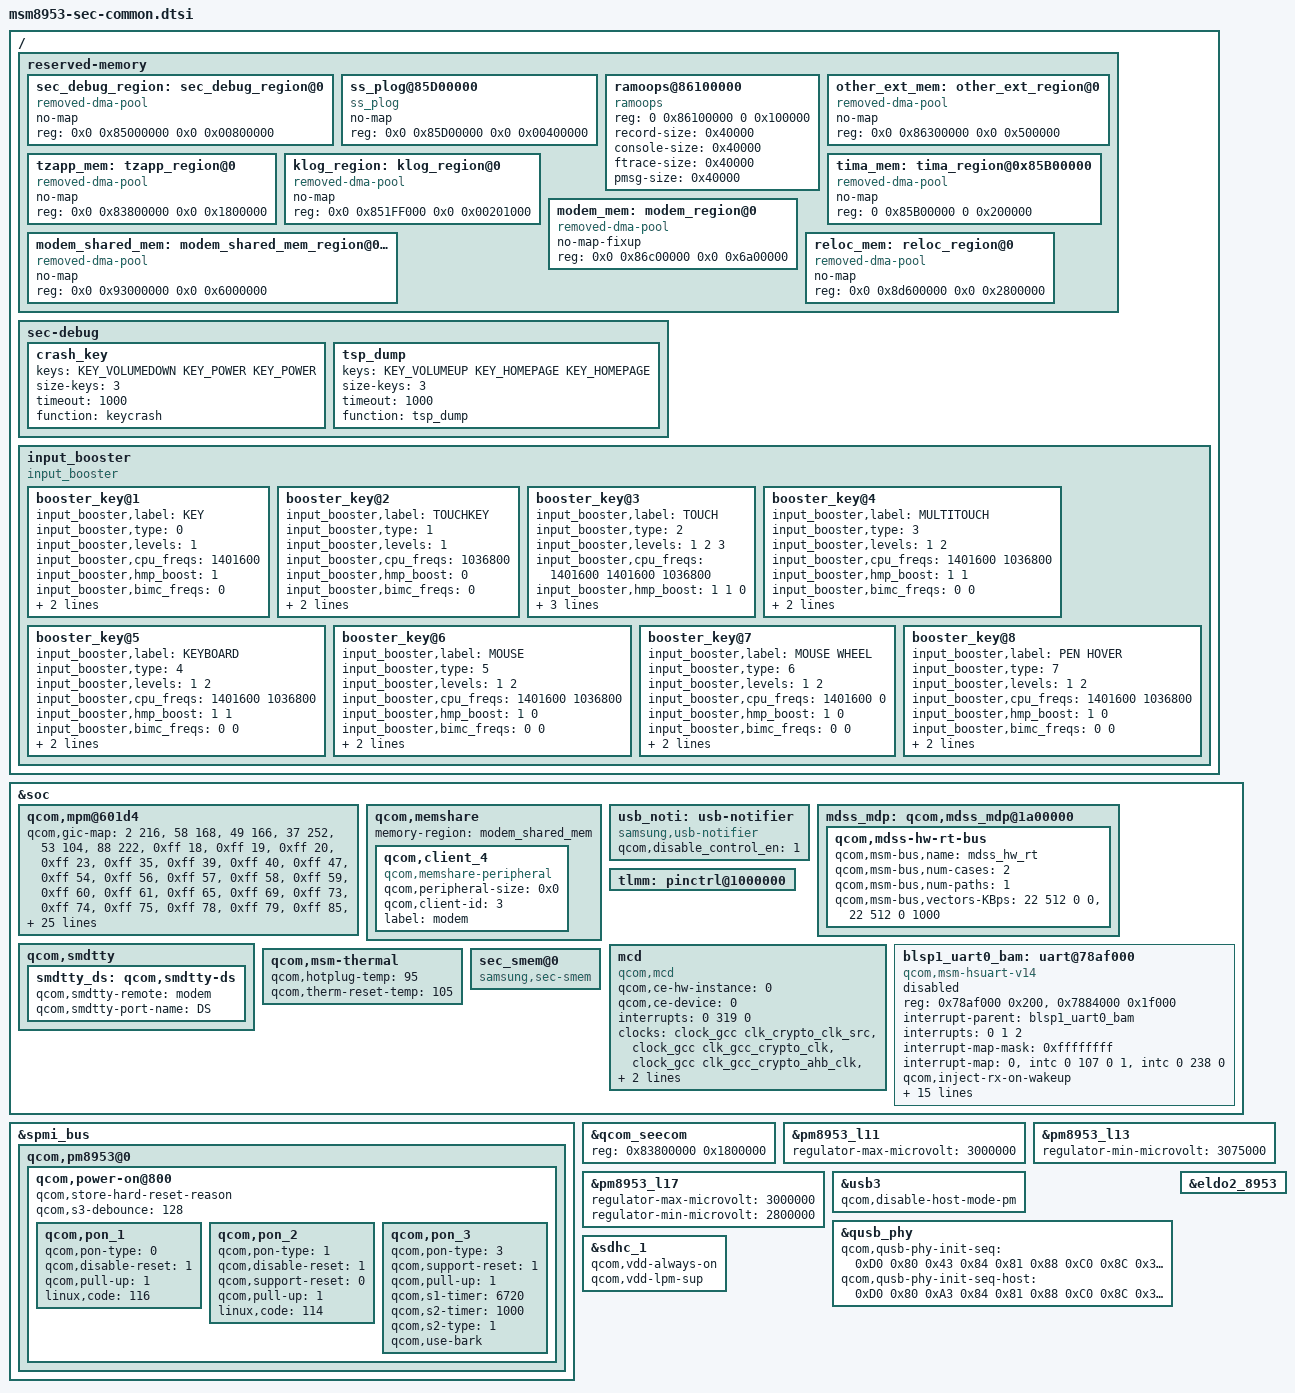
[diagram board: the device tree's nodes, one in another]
/*
 * Copyright (c) 2015-2016, The Linux Foundation. All rights reserved.
 *
 * This program is free software; you can redistribute it and/or modify
 * it under the terms of the GNU General Public License version 2 and
 * only version 2 as published by the Free Software Foundation.
 *
 * This program is distributed in the hope that it will be useful,
 * but WITHOUT ANY WARRANTY; without even the implied warranty of
 * MERCHANTABILITY or FITNESS FOR A PARTICULAR PURPOSE.  See the
 * GNU General Public License for more details.
 */

#include <dt-bindings/input/input.h>

/ {
	reserved-memory {
		/* CONFIG_SEC_DEBUG reserves 8MB */
		sec_debug_region: sec_debug_region@0 {
			compatible = "removed-dma-pool";
			no-map;
			reg = <0x0 0x85000000 0x0 0x00800000>;
		};
		ss_plog@85D00000 {
			compatible = "ss_plog";
			no-map;
			reg = <0x0 0x85D00000 0x0 0x00400000>;
		};
		ramoops@86100000 {
			compatible = "ramoops";
			reg = <0 0x86100000 0 0x100000>;
			record-size = <0x40000>;
			console-size = <0x40000>;
			ftrace-size = <0x40000>;
			pmsg-size = <0x40000>;
		};
		other_ext_mem: other_ext_region@0 {
			compatible = "removed-dma-pool";
			no-map;
			reg = <0x0 0x86300000 0x0 0x500000>;
		};
		tzapp_mem: tzapp_region@0 {
			compatible = "removed-dma-pool";
			no-map;
			reg = <0x0 0x83800000 0x0 0x1800000>;
		};

		/* klog_region reserves 2.01MB
		   This region is reserved if only debuglevel low */
		klog_region: klog_region@0 {
			compatible = "removed-dma-pool";
			no-map;
			reg = <0x0 0x851FF000 0x0 0x00201000>;
		};

		/*to reserve 2MB for TIMA */
		tima_mem: tima_region@0x85B00000 {
		    compatible = "removed-dma-pool";
		    no-map;
		    reg = <0 0x85B00000 0 0x200000>;
		};

		modem_shared_mem: modem_shared_mem_region@0x93000000 {
			compatible = "removed-dma-pool";
			no-map;
			reg = <0x0 0x93000000 0x0 0x6000000>;
		};

		/delete-node/ modem_region@0;
		modem_mem: modem_region@0 {
			compatible = "removed-dma-pool";
			no-map-fixup;
			reg = <0x0 0x86c00000 0x0 0x6a00000>;
		};

		/delete-node/ reloc_region@0;
		reloc_mem: reloc_region@0 {
			compatible = "removed-dma-pool";
			no-map;
			reg = <0x0 0x8d600000 0x0 0x2800000>;
		};
	};

	sec-debug {
		crash_key {
			keys = <KEY_VOLUMEDOWN KEY_POWER KEY_POWER>;
			size-keys = <3>;
			timeout = <1000>;	/* default = 1000msec */
			function = "keycrash";
		};

		 tsp_dump {
			keys = <KEY_VOLUMEUP KEY_HOMEPAGE KEY_HOMEPAGE>;
			size-keys = <3>;
			timeout = <1000>;
			function = "tsp_dump";
		};
	};

	input_booster {
		status = "okay";
		compatible = "input_booster";
		#address-cells = <1>;
		#size-cells = <0>;

		booster_key@1 {
			input_booster,label = "KEY";
			input_booster,type = <0>;	/* BOOSTER_DEVICE_KEY */

			input_booster,levels = <1>;

			/* Frequency table */
			/* for level	:	1_Head */
			input_booster,cpu_freqs = <1401600>;
			input_booster,hmp_boost = <1>;
			input_booster,bimc_freqs = <0>;

			/* Time table */
			input_booster,head_times = <200>;
			input_booster,tail_times = <200>;

		};
		booster_key@2 {
			input_booster,label = "TOUCHKEY";
			input_booster,type = <1>;	/* BOOSTER_DEVICE_TOUCHKEY */

			input_booster,levels = <1>;

			/* Frequency table */
			/* for level	:	1_Head */
			input_booster,cpu_freqs = <1036800>;
			input_booster,hmp_boost = <0>;
			input_booster,bimc_freqs = <0>;

			/* Time table */
			input_booster,head_times = <0>;
			input_booster,tail_times = <300>;
		};
		booster_key@3 {
			input_booster,label = "TOUCH";
			input_booster,type = <2>;	/* BOOSTER_DEVICE_TOUCH */

			input_booster,levels = <1 2 3>;

			/* Frequency table */
			/* for level	:	1_Head, 2_Head, 2_Tail */
			input_booster,cpu_freqs = <1401600 1401600 1036800>;
			input_booster,hmp_boost = <1 1 0>;
			input_booster,bimc_freqs = <0 0 0>;

			/* Time table */
			input_booster,head_times = <200 200 0>;
			input_booster,tail_times = <0 0 300>;
		};
		booster_key@4 { // Input Booster +
			input_booster,label = "MULTITOUCH";
			input_booster,type = <3>;	/* BOOSTER_DEVICE_MULTITOUCH */

			input_booster,levels = <1 2>;

			/* Frequency table */
			/* for level	:	1_Head 2_Tail*/
			input_booster,cpu_freqs = <1401600 1036800>;
			input_booster,hmp_boost = <1 1>;
			input_booster,bimc_freqs = <0 0>;

			/* Time table */
			input_booster,head_times = <1000 0>;
			input_booster,tail_times = <0 500>;
		};
		booster_key@5 {
			input_booster,label = "KEYBOARD";
			input_booster,type = <4>;	/* BOOSTER_DEVICE_KEYBOARD */

			input_booster,levels = <1 2>;

			/* Frequency table */
			/* for level	:	1_Head 2_Tail*/
			input_booster,cpu_freqs = <1401600 1036800>;
			input_booster,hmp_boost = <1 1>;
			input_booster,bimc_freqs = <0 0>;

			/* Time table */
			input_booster,head_times = <200 200>;
			input_booster,tail_times = <0 0>;
		};
		booster_key@6 {
			input_booster,label = "MOUSE";
			input_booster,type = <5>;	/* BOOSTER_DEVICE_MOUSE */

			input_booster,levels = <1 2>;

			/* Frequency table */
			/* for level	:	1_Head 2_Tail*/
			input_booster,cpu_freqs = <1401600 1036800>;
			input_booster,hmp_boost = <1 0>;
			input_booster,bimc_freqs = <0 0>;

			/* Time table */
			input_booster,head_times = <200 0>;
			input_booster,tail_times = <0 300>;
		};
		booster_key@7 {
			input_booster,label = "MOUSE WHEEL";
			input_booster,type = <6>;	/* BOOSTER_DEVICE_MOUSE */

			input_booster,levels = <1 2>;

			/* Frequency table */
			/* for level	:	1_Head 2_Tail*/
			input_booster,cpu_freqs = <1401600 0>;
			input_booster,hmp_boost = <1 0>;
			input_booster,bimc_freqs = <0 0>;

			/* Time table */
			input_booster,head_times = <200 0>;
			input_booster,tail_times = <0 0>;
		};
		booster_key@8 {
			input_booster,label = "PEN HOVER";
			input_booster,type = <7>;	/* BOOSTER_DEVICE_MOUSE */

			input_booster,levels = <1 2>;

			/* Frequency table */
			/* for level	:	1_Head 2_Tail*/
			input_booster,cpu_freqs = <1401600 1036800>;
			input_booster,hmp_boost = <1 0>;
			input_booster,bimc_freqs = <0 0>;

			/* Time table */
			input_booster,head_times = <200 0>;
			input_booster,tail_times = <0 300>;
		}; // Input Booster -
		/* If you need to add new key type, add it this position */
	};
};

&soc {
	qcom,mpm@601d4 {
			/delete-property/ qcom,gic-map;
			qcom,gic-map = <2 216>, /* tsens_upper_lower_int */
			<58 168>,   /* qusb2phy_dmse_hv -> hs_phy_irq*/
			<49 166>,   /* qusb2phy_dpse_hv -> usb30_pwr_evnt_irq */
			<37 252>,   /* qmp_usb3_lfps_rxterm_irq -> ss_phy_irq */
			<53 104>, /* mdss_irq */
			<88 222>, /* ee0_krait_hlos_spmi_periph_irq */
			<0xff 18>,  /* APC_qgicQTmrSecPhysIrptReq */
			<0xff 19>,  /* APC_qgicQTmrNonSecPhysIrptReq */
			<0xff 20>,  /* qgicQTmrVirtIrptReq */
			<0xff 23>,  /* apss_hm */
			<0xff 35>,  /* WDT_barkInt */
			<0xff 39>,  /* arch_mem_timer */
			<0xff 40>,  /* qtmr_phy_irq[0] */
			<0xff 47>,  /* rbif_irq[0] */
			<0xff 54>,  /* gladiator-error */
			<0xff 56>,  /* q6_wdog_expired_irq */
			<0xff 57>,  /* mss_to_apps_irq(0) */
			<0xff 58>,  /* mss_to_apps_irq(1) */
			<0xff 59>,  /* mss_to_apps_irq(2) */
			<0xff 60>,  /* mss_to_apps_irq(3) */
			<0xff 61>,  /* mss_a2_bam_irq */
			<0xff 65>,  /* o_gc_sys_irq[0] */
			<0xff 69>,  /* vbif_irpt */
			<0xff 73>,  /* app_tcu_gbl_flt_irpt_ns */
			<0xff 74>,  /* smmu_bus_intr[2] */
			<0xff 75>,  /* smmu_bus_intr[3] */
			<0xff 78>,  /* smmu_bus_intr[5] */
			<0xff 79>,  /* smmu_bus_intr[6] */
			<0xff 85>,  /* smmu_bus_intr[31] */
			<0xff 86>,  /* smmu_bus_intr[32] */
			<0xff 90>,  /* smmu_bus_intr[33] */
			<0xff 92>,  /* smmu_bus_intr[34] */
			<0xff 93>,  /* smmu_bus_intr[35] */
			<0xff 97>,  /* smmu_bus_intr[10] */
			<0xff 102>, /* smmu_bus_intr[14] */
			<0xff 108>, /* smmu_bus_intr[36] */
			<0xff 109>, /* smmu_bus_intr[37] */
			<0xff 112>, /* smmu_bus_intr[38] */
			<0xff 114>, /* qdsd_intr_out */
			<0xff 126>, /* app_tcu_cxt_irpt_vec[11] */
			<0xff 128>, /* blsp1_peripheral_irq[3] */
			<0xff 131>, /* qup_irq */
			<0xff 136>, /* app_tcu_cxt_irpt_vec[15] */
			<0xff 137>, /* app_tcu_cxt_irpt_vec[16] */
			<0xff 138>, /* app_tcu_cxt_irpt_vec[17] */
			<0xff 139>, /* uart_dm_intr */
			<0xff 140>, /* uart_dm_intr */
			<0xff 141>, /* app_tcu_cxt_irpt_vec[18] */
			<0xff 142>, /* smmu_bus_intr[47] */
			<0xff 143>, /* smmu_bus_intr[48] */
			<0xff 144>, /* smmu_bus_intr[49] */
			<0xff 145>, /* smmu_bus_intr[50] */
			<0xff 146>, /* smmu_bus_intr[51] */
			<0xff 147>, /* smmu_bus_intr[52] */
			<0xff 148>, /* smmu_bus_intr[53] */
			<0xff 149>, /* smmu_bus_intr[54] */
			<0xff 150>, /* smmu_bus_intr[55] */
			<0xff 151>, /* smmu_bus_intr[56] */
			<0xff 152>, /* smmu_bus_intr[57] */
			<0xff 153>, /* smmu_bus_intr[58] */
			<0xff 155>, /* sdc1_irq(0) */
			<0xff 157>, /* sdc2_irq(0) */
			<0xff 167>, /* usb30_bam_irq[0] */
			<0xff 170>, /* sdc1_pwr_cmd_irq */
			<0xff 172>, /* usb30_ctrl_irq[0] */
			<0xff 173>, /* o_wcss_apss_smd_hi */
			<0xff 174>, /* o_wcss_apss_smd_med */
			<0xff 175>, /* o_wcss_apss_smd_low */
			<0xff 176>, /* o_wcss_apss_smsm_irq */
			<0xff 177>, /* o_wcss_apss_wlan_data_xfer_done */
			<0xff 178>, /* o_wcss_apss_wlan_rx_data_avail */
			<0xff 179>, /* o_wcss_apss_asic_intr */
			<0xff 181>, /* o_wcss_apss_wdog_bite_and_reset_rdy */
			<0xff 188>, /* lpass_irq_out_apcs(0) */
			<0xff 189>, /* lpass_irq_out_apcs(1) */
			<0xff 190>, /* lpass_irq_out_apcs(2) */
			<0xff 191>, /* lpass_irq_out_apcs(3) */
			<0xff 192>, /* lpass_irq_out_apcs(4) */
			<0xff 193>, /* lpass_irq_out_apcs(5) */
			<0xff 194>, /* lpass_irq_out_apcs(6) */
			<0xff 195>, /* lpass_irq_out_apcs(7) */
			<0xff 196>, /* lpass_irq_out_apcs(8) */
			<0xff 197>, /* lpass_irq_out_apcs(9) */
			<0xff 198>, /* coresight-tmc-etr interrupt */
			<0xff 200>, /* rpm_ipc(4) */
			<0xff 201>, /* rpm_ipc(5) */
			<0xff 202>, /* rpm_ipc(6) */
			<0xff 203>, /* rpm_ipc(7) */
			<0xff 204>, /* rpm_ipc(24) */
			<0xff 205>, /* rpm_ipc(25) */
			<0xff 206>, /* rpm_ipc(26) */
			<0xff 207>, /* rpm_ipc(27) */
			<0xff 212>, /* lpass_slimbus_bam_ee1_irq */
			<0xff 215>, /* o_bimc_intr[0] */
			<0xff 224>, /* spdm_realtime_irq[1] */
			<0xff 231>, /* arm-smmu global fault */
			<0xff 239>, /* crypto_bam_irq[1]*/
			<0xff 240>, /* summary_irq_kpss */
			<0xff 253>, /* sdc2_pwr_cmd_irq */
			<0xff 257>, /* osmmu_Cirpt[0] */
			<0xff 260>, /* ipa_irq[0] */
			<0xff 262>, /* ipa_bam_irq[0] */
			<0xff 263>, /* ipa_bam_irq[2] */
			<0xff 264>, /* arm-smmu context fault */
			<0xff 269>, /* rpm_wdog_expired_irq */
			<0xff 270>, /* blsp1_bam_irq[0] */
			<0xff 271>,
			<0xff 273>, /* smmu_bus_intr[18] */
			<0xff 274>, /* smmu_bus_intr[19] */
			<0xff 275>, /* rpm_ipc(30) */
			<0xff 276>, /* rpm_ipc(31) */
			<0xff 285>, /* app_tcu_cxt_irpt_vec[0] */
			<0xff 286>, /* app_tcu_cxt_irpt_vec[1] */
			<0xff 287>, /* app_tcu_cxt_irpt_vec[2] */
			<0xff 305>, /* L2_EXTERRIRQ_C0 */
			<0xff 306>, /* L2_EXTERRIRQ_C1 */
			<0xff 307>, /* L2_INTERRIRQ_C0 */
			<0xff 308>, /* L2_INTERRIRQ_C1 */
			<0xff 314>, /* CCISAW_svicInt */
			<0xff 321>, /* q6ss_irq_out(4) */
			<0xff 322>, /* q6ss_irq_out(5) */
			<0xff 323>, /* q6ss_irq_out(6) */
			<0xff 325>, /* q6ss_wdog_exp_irq */
			<0xff 331>,
			<0xff 344>, /* sdcc_ice_nonsec_level_irq */
			<0xff 346>, /* tsens_critical_int */
			<0xff 351>; /* trustonic */
	};

	qcom,memshare {
		memory-region = <&modem_shared_mem>;

		qcom,client_4 {
			compatible = "qcom,memshare-peripheral";
			qcom,peripheral-size = <0x0>;
			qcom,client-id = <3>;	/* vendor */
			label = "modem";
		};
	};

	usb_noti:usb-notifier {
		compatible = "samsung,usb-notifier";
		qcom,disable_control_en = <1>;
	};

	mdss_mdp: qcom,mdss_mdp@1a00000 {
		qcom,mdss-hw-rt-bus {
			/* Bus Scale Settings */
			qcom,msm-bus,name = "mdss_hw_rt";
			qcom,msm-bus,num-cases = <2>;
			qcom,msm-bus,num-paths = <1>;
			qcom,msm-bus,vectors-KBps =
				<22 512 0 0>,
				<22 512 0 1000>;
		};
	};

	tlmm: pinctrl@1000000 {
		/delete-node/ pmx_rd_nfc_int;
	};


	qcom,smdtty {
		smdtty_ds: qcom,smdtty-ds {
			qcom,smdtty-remote = "modem";
			qcom,smdtty-port-name = "DS";
		};
	};

	mcd: mcd {
		compatible = "qcom,mcd";
		qcom,ce-hw-instance = <0>;
		qcom,ce-device = <0>;
		interrupts = <0 319 0>;
		interrupt-names = "mcd_irq";
		clocks = <&clock_gcc clk_crypto_clk_src>,
			 <&clock_gcc clk_gcc_crypto_clk>,
			 <&clock_gcc clk_gcc_crypto_ahb_clk>,
			 <&clock_gcc clk_gcc_crypto_axi_clk>;
		clock-names = "core_clk_src", "core_clk",
				"iface_clk", "bus_clk";
		qcom,ce-opp-freq = <100000000>;
	};

	blsp1_uart0_bam: uart@78af000 {
		compatible = "qcom,msm-hsuart-v14";
		reg = <0x78af000 0x200>,
			<0x7884000 0x1f000>;
		reg-names = "core_mem", "bam_mem";

		interrupt-names = "core_irq", "bam_irq";
		#address-cells = <0>;
		interrupt-parent = <&blsp1_uart0_bam>;
		interrupts = <0 1 2>;
		#interrupt-cells = <1>;
		interrupt-map-mask = <0xffffffff>;
		interrupt-map = <0 &intc 0 107 0
				1 &intc 0 238 0>;

		qcom,inject-rx-on-wakeup;
		qcom,rx-char-to-inject = <0xFD>;
		qcom,master-id = <86>;
		clock-names = "core_clk", "iface_clk";
		clocks = <&clock_gcc clk_gcc_blsp1_uart1_apps_clk>,
			<&clock_gcc clk_gcc_blsp1_ahb_clk>;
		pinctrl-names = "sleep", "default";
		pinctrl-0 = <&hsuart_sleep>;
		pinctrl-1 = <&hsuart_active>;
		qcom,bam-tx-ep-pipe-index = <0>;
		qcom,bam-rx-ep-pipe-index = <1>;
		qcom,msm-bus,name = "blsp1_uart0_bam";
		qcom,msm-bus,num-cases = <2>;
		qcom,msm-bus,num-paths = <1>;
		qcom,msm-bus,vectors-KBps =
				<86 512 0 0>,
				<86 512 500 800>;
		status = "disabled";
		qcom,unuse-pm;
	};
	
	qcom,msm-thermal {
		qcom,hotplug-temp = <95>;
		qcom,therm-reset-temp = <105>;
	};

	sec_smem@0 {
		compatible = "samsung,sec-smem";
		status = "okay";
	};
};

&spmi_bus {
	qcom,pm8953@0 {
		qcom,power-on@800 {
			qcom,store-hard-reset-reason;

			qcom,s3-debounce = <128>;
			qcom,pon_1 {
				qcom,pon-type = <0>;
				qcom,disable-reset = <1>;
				qcom,pull-up = <1>;
				linux,code = <116>;
			};

			qcom,pon_2 {
				qcom,pon-type = <1>;
				qcom,disable-reset = <1>;
				qcom,support-reset = <0>;
				qcom,pull-up = <1>;
				linux,code = <114>;
			};

			qcom,pon_3 {
				qcom,pon-type = <3>;
				qcom,support-reset = <1>;
				qcom,pull-up = <1>;
				qcom,s1-timer = <6720>;
				qcom,s2-timer = <1000>;
				qcom,s2-type = <1>;
				qcom,use-bark;
			};
		};


	};
};

&qcom_seecom {
	reg = <0x83800000 0x1800000>;
};

&pm8953_l11 {
	regulator-max-microvolt = <3000000>;
};

&pm8953_l13 {
	regulator-min-microvolt = <3075000>;
};

&pm8953_l17 {
	regulator-max-microvolt = <3000000>;
	regulator-min-microvolt = <2800000>;
};

&usb3 {
	/delete-property/ vbus_dwc3-supply;
	qcom,disable-host-mode-pm;
};

&qusb_phy {
	qcom,qusb-phy-init-seq = <0xD0 0x80
				0x43 0x84
				0x81 0x88
				0xC0 0x8C
				0x30 0x08
				0x79 0x0C
				0x21 0x10
				0x14 0x9C
				0x9F 0x1C
				0x00 0x18>;
	qcom,qusb-phy-init-seq-host = <0xD0 0x80
				0xA3 0x84
				0x81 0x88
				0xC0 0x8C
				0x30 0x08
				0x79 0x0C
				0x21 0x10
				0x14 0x9C
				0x9F 0x1C
				0x00 0x18>;
};

&eldo2_8953 {
	/delete-property/ gpio;
};

&sdhc_1 {
	qcom,vdd-always-on;
	qcom,vdd-lpm-sup;
};
